# STM32U5A9 register map
File version: 0.2
CPU: CM33 r0p1, little endian, MPU, FPU, 4 interrupt priority bits
Registers are 32-bit, read-write, reset 0x0 unless marked. A register's access mark holds for its fields unless they carry their own. Offsets are from the block's base; [hi:lo] are bit positions.

## RNG — Random number generator
Base 0x420C0800
Same registers: SEC_RNG 0x520C0800
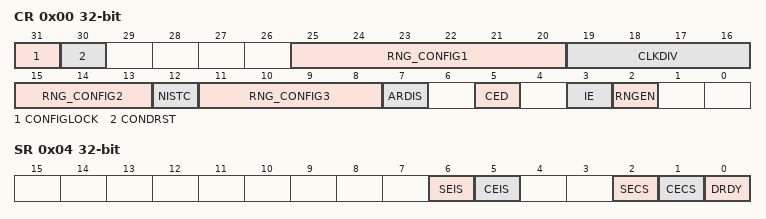
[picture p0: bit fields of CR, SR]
0x00 CR — control register
  [31] CONFIGLOCK — RNG Config Lock
  [30] CONDRST — Conditioning soft reset
  [25:20] RNG_CONFIG1 — RNG configuration 1
  [19:16] CLKDIV — Clock divider factor
  [15:13] RNG_CONFIG2 — RNG configuration 2
  [12] NISTC — Non NIST compliant
  [11:8] RNG_CONFIG3 — RNG configuration 3
  [7] ARDIS — Auto reset disable
  [5] CED — Clock error detection
  [3] IE — Interrupt Enable
  [2] RNGEN — True random number generator enable
0x04 SR access per field — status register
  [6] SEIS rw — Seed error interrupt status
  [5] CEIS rw — Clock error interrupt status
  [2] SECS ro — Seed error current status
  [1] CECS ro — Clock error current status
  [0] DRDY ro — Data ready
0x08 DR ro — data register
  [31:0] RNDATA — Random data
0x10 HTCR reset 0x6274 — health test control register
  [31:0] HTCFG — health test configuration

## SPI1 — Serial peripheral interface
Base 0x40013000
Same registers: SPI2 0x40003800, SPI3 0x46002000, SEC_SPI2 0x50003800, SEC_SPI1 0x50013000, SEC_SPI3 0x56002000
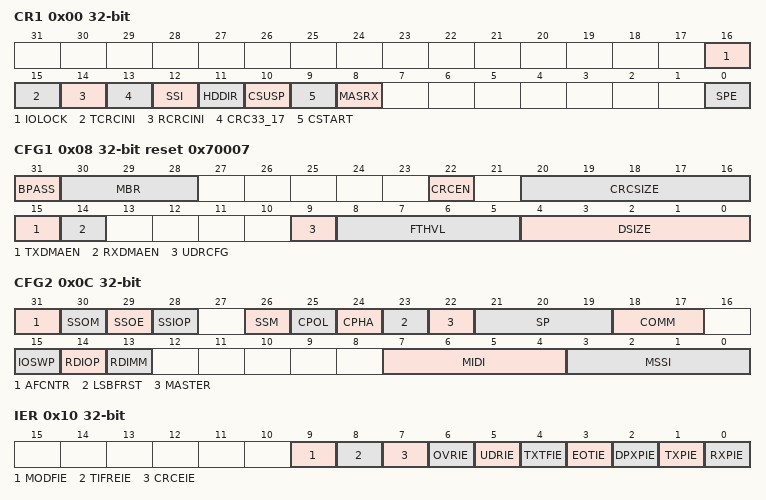
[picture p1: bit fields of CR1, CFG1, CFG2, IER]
0x00 CR1 access per field — control register 1
  [16] IOLOCK rw, [15] TCRCINI rw, [14] RCRCINI rw, [13] CRC33_17 rw, [12] SSI rw, [11] HDDIR rw, [10] CSUSP wo, [9] CSTART rw, [8] MASRX rw, [0] SPE rw
0x04 CR2 — control register 2
  [15:0] TSIZE
0x08 CFG1 reset 0x70007 — configuration register 1
  [31] BPASS
  [30:28] MBR — Master baud rate
  [22] CRCEN — Hardware CRC computation enable
  [20:16] CRCSIZE — Length of CRC frame to be transacted and compared
  [15] TXDMAEN — Tx DMA stream enable
  [14] RXDMAEN — Rx DMA stream enable
  [9] UDRCFG — Behavior of slave transmitter at underrun condition
  [8:5] FTHVL — threshold level
  [4:0] DSIZE — Number of bits in at single SPI data frame
0x0C CFG2 — configuration register 2
  [31] AFCNTR — Alternate function GPIOs control
  [30] SSOM — SS output management in master mode
  [29] SSOE — SS output enable
  [28] SSIOP — SS input/output polarity
  [26] SSM — Software management of SS signal input
  [25] CPOL — Clock polarity
  [24] CPHA — Clock phase
  [23] LSBFRST — Data frame format
  [22] MASTER — SPI Master
  [21:19] SP — Serial Protocol
  [18:17] COMM — SPI Communication Mode
  [15] IOSWP — Swap functionality of MISO and MOSI pins
  [14] RDIOP
  [13] RDIMM
  [7:4] MIDI — Master Inter-Data Idleness
  [3:0] MSSI — Master SS Idleness
0x10 IER — Interrupt Enable Register
  [9] MODFIE — Mode Fault interrupt enable
  [8] TIFREIE — TIFRE interrupt enable
  [7] CRCEIE — CRC Interrupt enable
  [6] OVRIE — OVR interrupt enable
  [5] UDRIE — UDR interrupt enable
  [4] TXTFIE — TXTFIE interrupt enable
  [3] EOTIE — EOT, SUSP and TXC interrupt enable
  [2] DPXPIE — DXP interrupt enabled
  [1] TXPIE — TXP interrupt enable
  [0] RXPIE — RXP Interrupt Enable
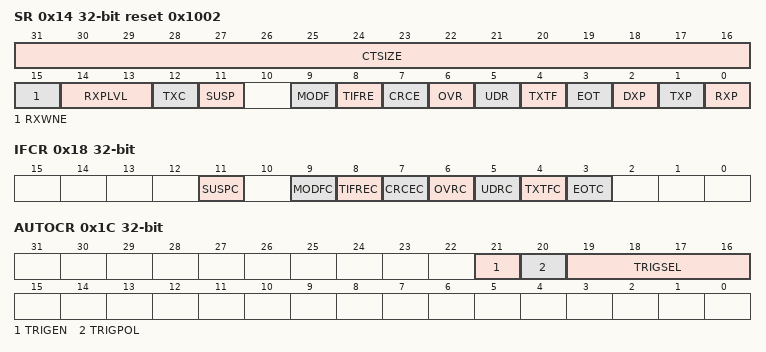
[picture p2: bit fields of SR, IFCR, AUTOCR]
0x14 SR ro reset 0x1002 — Status Register
  [31:16] CTSIZE — Number of data frames remaining in current TSIZE session
  [15] RXWNE — RxFIFO Word Not Empty
  [14:13] RXPLVL — RxFIFO Packing LeVeL
  [12] TXC — TxFIFO transmission complete
  [11] SUSP — SUSPend
  [9] MODF — Mode Fault
  [8] TIFRE — TI frame format error
  [7] CRCE — CRC Error
  [6] OVR — Overrun
  [5] UDR — Underrun at slave transmission mode
  [4] TXTF — Transmission Transfer Filled
  [3] EOT — End Of Transfer
  [2] DXP — Duplex Packet
  [1] TXP — Tx-Packet space available
  [0] RXP — Rx-Packet available
0x18 IFCR wo — Interrupt/Status Flags Clear Register
  [11] SUSPC — SUSPend flag clear
  [9] MODFC — Mode Fault flag clear
  [8] TIFREC — TI frame format error flag clear
  [7] CRCEC — CRC Error flag clear
  [6] OVRC — Overrun flag clear
  [5] UDRC — Underrun flag clear
  [4] TXTFC — Transmission Transfer Filled flag clear
  [3] EOTC — End Of Transfer flag clear
0x1C AUTOCR — SPI autonomous mode control register
  [21] TRIGEN, [20] TRIGPOL, [19:16] TRIGSEL
0x20 TXDR wo — Transmit Data Register
  [31:0] TXDR — Transmit data register
0x30 RXDR ro — Receive Data Register
  [31:0] RXDR — Receive data register
0x40 CRCPOLY reset 0x107 — Polynomial Register
  [31:0] CRCPOLY — CRC polynomial register
0x44 TXCRC ro — Transmitter CRC Register
  [31:0] TXCRC — CRC register for transmitter
0x48 RXCRC ro — Receiver CRC Register
  [31:0] RXCRC — CRC register for receiver
0x4C UDRDR — Underrun Data Register
  [31:0] UDRDR — Data at slave underrun condition
